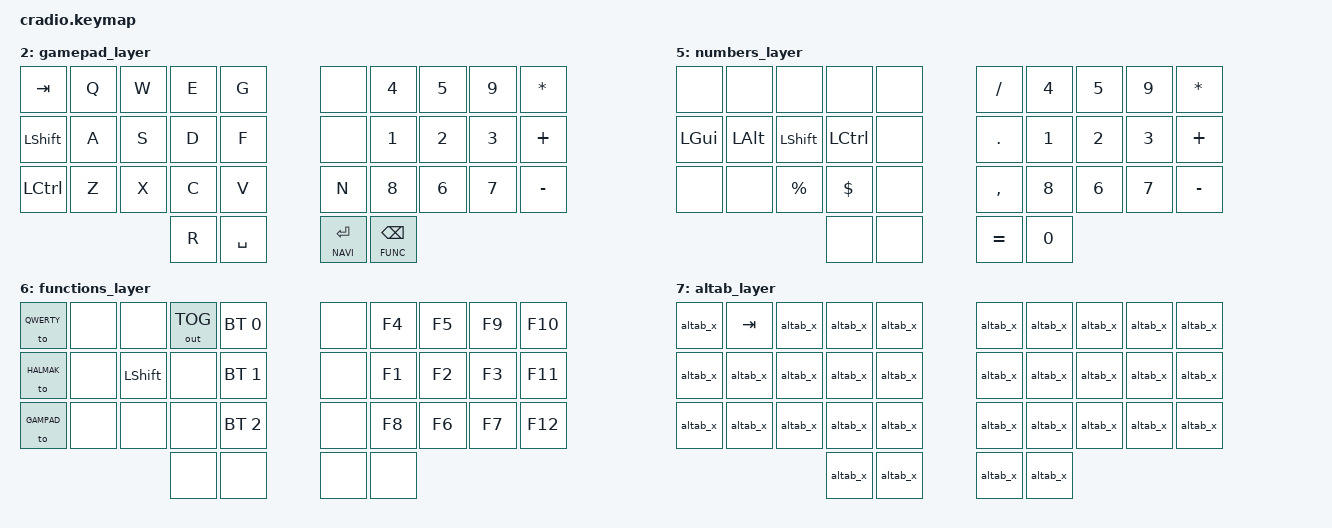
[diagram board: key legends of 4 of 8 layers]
// Copyright (c) 2022 The ZMK Contributors
// Copyright (c) 2022 Kai Evans
// SPDX-License-Identifier: MIT

#include <behaviors.dtsi>
#include <dt-bindings/zmk/outputs.h>
#include <dt-bindings/zmk/keys.h>
#include <dt-bindings/zmk/bt.h>

&lt {
	flavor = "hold-preferred";
};

&caps_word {
	continue-list = <UNDER MINUS BSPC RSHFT LSHFT>;
};

#define HALMAK 0
#define QWERTY 1
#define GAMPAD 2
#define NAVI   3
#define EDIT   4
#define NUMS   5
#define FUNC   6
#define ALTAB  7

#define QWERTY_MOD_MACRO(name, mod)            \
name: name##_macro {                           \
	label = #name;                             \
	compatible = "zmk,behavior-macro";         \
	#binding-cells = <0>;                      \
	wait-ms = <0>;                             \
    bindings                                   \
        = <&macro_press &mo QWERTY &kp mod>    \
        , <&macro_pause_for_release>           \
        , <&macro_release &mo QWERTY &kp mod>; \
};

/ {
    macros {
        QWERTY_MOD_MACRO(qalt, LALT)
        QWERTY_MOD_MACRO(qgui, LGUI)
        QWERTY_MOD_MACRO(qctl, LCTRL)

        // the edit layer altab
        edit_altab_halmak: edit_altab_layer_tap_halmak {
            label = "edit_altab_layer_tap_halmak";
            compatible = "zmk,behavior-macro";
	        #binding-cells = <0>;
	        wait-ms = <0>;
            tap-ms = <0>;
            bindings
                = <&macro_press &to EDIT>
                , <&macro_pause_for_release>
                , <&macro_release &kp LCTRL>
                , <&macro_tap &to HALMAK>;
        };

        edit_altab_qwerty: edit_altab_layer_tap_qwerty {
            label = "edit_altab_layer_tap_qwerty";
            compatible = "zmk,behavior-macro";
	        #binding-cells = <0>;
	        wait-ms = <0>;
            tap-ms = <0>;
            bindings
                = <&macro_press &to EDIT>
                , <&macro_pause_for_release>
                , <&macro_release &kp LCTRL>
                , <&macro_tap &to QWERTY>;
        };

        altab: alt_tab_enter {
            label = "alt_tab_enter";
            compatible = "zmk,behavior-macro";
            #binding-cells = <0>;
            wait-ms = <10>;
            tap-ms = <20>;
            bindings =
                <&macro_press &kp LCTRL>,
                <&macro_tap &kp TAB &to ALTAB>;
        };
        altab_x: alt_tab_leave {
            label = "alt_tab_leave";
            compatible = "zmk,behavior-macro";
            #binding-cells = <0>;
            wait-ms = <10>;
            tap-ms = <20>;
            bindings =
                <&macro_release &kp LCTRL>,
                <&macro_tap &to 0>;
        };
    };
};

#define HOME_ROW_MOD_TAP(name, macro)      \
name: name##_mod_tap {                     \
    label = #name;                         \
    compatible = "zmk,behavior-hold-tap";  \
    #binding-cells = <2>;                  \
    flavor = "balanced";                   \
    tapping-term-ms = <200>;               \
    quick-tap-ms = <150>;                  \
    global-quick-tap;                      \
    bindings = <macro>, <&kp>;             \
};

/ {
    behaviors {
        HOME_ROW_MOD_TAP(ht_alt, &qalt)
        HOME_ROW_MOD_TAP(ht_gui, &qgui)
        HOME_ROW_MOD_TAP(ht_ctl, &qctl)
        sht: quick_hold_tap {
            label = "quick_hold_tap";
            compatible = "zmk,behavior-hold-tap";
            #binding-cells = <2>;
            flavor = "balanced";
            tapping-term-ms = <170>;
            quick-tap-ms = <130>;
            global-quick-tap;
            bindings = <&kp>, <&kp>;
        };
        eth: edit_layer_tap_halmak {
            label = "edit_layer_with_altab_halmak";
            compatible = "zmk,behavior-hold-tap";
            flavor = "tap-preferred";
            tapping-term-ms = <200>;
            #binding-cells = <2>;
            bindings = <&edit_altab_halmak>, <&kp>;
        };
        etq: edit_layer_tap_qwerty {
            label = "edit_layer_with_altab_qwerty";
            compatible = "zmk,behavior-hold-tap";
            flavor = "tap-preferred";
            tapping-term-ms = <200>;
            #binding-cells = <2>;
            bindings = <&edit_altab_qwerty>, <&kp>;
        };
    };
};

#define HRML(k1,k2,k3,k4) &ht_gui 0 k1  &ht_alt 0 k2  &sht LSHFT k3  &ht_ctl 0 k4
#define HRMR(k1,k2,k3,k4) &ht_ctl 0 k1  &sht RSHFT k2  &ht_alt 0 k3  &ht_gui 0 k4


/ {
    keymap {
        compatible = "zmk,keymap";
        halmak_layer {
            bindings = <
        //╭──────────┬──────────┬──────────┬──────────┬──────────╮   ╭──────────┬──────────┬──────────┬──────────┬──────────╮
        //│  W       │  L       │  R       │  B       │  Z       │   │  ;       │  Q       │  U       │  D       │  J       │
            &kp W      &kp L      &kp R      &kp B      &kp Z          &kp SEMI   &kp Q      &kp U      &kp D      &kp J
        //├──────────┼──────────┼──────────┼──────────┼──────────┤   ├──────────┼──────────┼──────────┼──────────┼──────────┤
        //│  S       │  H       │  N       │  T       │  ,       │   │  .       │  A       │  E       │  O       │  I       │
            HRML(S,        H,         N,         T)     &kp COMMA      &kp DOT   HRMR(A,        E,         O,        I)
        //├──────────┼──────────┼──────────┼──────────┼──────────┤   ├──────────┼──────────┼──────────┼──────────┼──────────┤
        //│  F       │  M       │  V       │  C       │  /       │   │  G       │  P       │  X       │  K       │  Y       │
            &kp F      &kp M      &kp V      &kp C      &kp FSLH          &kp G      &kp P   &kp X     &kp K       &kp Y
        //╰──────────┴──────────┴──────────┼──────────┼──────────┤   ├──────────┼──────────┼──────────┴──────────┴──────────╯
                                       &lt NUMS TAB  &eth EDIT SPACE  &lt NAVI ENTER &lt FUNC BSPC
        //                                 ╰──────────┴──────────╯   ╰──────────┴──────────╯
            >;
        };

        qwerty_layer {
            bindings = <
        //╭──────────┬──────────┬──────────┬──────────┬──────────╮   ╭──────────┬──────────┬──────────┬──────────┬──────────╮
        //│  Q       │  W       │  E       │  R       │  T       │   │  Y       │  U       │  I       │  O       │  P       │
            &kp Q      &kp W      &kp E      &kp R      &kp T          &kp Y      &kp U      &kp I      &kp O      &kp P
        //├──────────┼──────────┼──────────┼──────────┼──────────┤   ├──────────┼──────────┼──────────┼──────────┼──────────┤
        //│  A       │  S       │  D       │  F       │  G       │   │  H       │  J       │  K       │  L       │ ;        │
            HRML(A,        S,         D,         F)     &kp G          &kp H      HRMR(J,        K,         L,        SEMI)
        //├──────────┼──────────┼──────────┼──────────┼──────────┤   ├──────────┼──────────┼──────────┼──────────┼──────────┤
        //│  Z       │  X       │  C       │  V       │  B       │   │  N       │  M       │ , <      │ . >      │ / ?      │
            &kp Z      &kp X      &kp C      &kp V      &kp B          &kp N      &kp M      &kp COMMA  &kp DOT    &kp FSLH
        //╰──────────┴──────────┴──────────┼──────────┼──────────┤   ├──────────┼──────────┼──────────┴──────────┴──────────╯
                                       &lt NUMS TAB  &etq EDIT SPACE  &lt NAVI ENTER &lt FUNC BSPC
        //                                 ╰──────────┴──────────╯   ╰──────────┴──────────╯
            >;
        };

        gamepad_layer {
            bindings = <
        //╭──────────┬──────────┬──────────┬──────────┬──────────╮   ╭──────────┬──────────┬──────────┬──────────┬──────────╮
        //│          │          │          │          │          │   │          │          │          │          │          │
          &kp TAB    &kp Q      &kp W      &kp E      &kp G          &none      &kp N4     &kp N5     &kp N9     &kp STAR
        //├──────────┼──────────┼──────────┼──────────┼──────────┤   ├──────────┼──────────┼──────────┼──────────┼──────────┤
        //│          │          │          │          │          │   │          │          │          │          │          │
          &kp LSHFT  &kp A      &kp S      &kp D      &kp F          &none      &kp N1     &kp N2     &kp N3     &kp PLUS 
        //├──────────┼──────────┼──────────┼──────────┼──────────┤   ├──────────┼──────────┼──────────┼──────────┼──────────┤
        //│          │          │          │          │          │   │          │          │          │          │          │
          &kp LCTRL  &kp Z      &kp X      &kp C      &kp V          &kp N      &kp N8     &kp N6     &kp N7     &kp MINUS
        //╰──────────┴──────────┴──────────┼──────────┼──────────┤   ├──────────┼──────────┼──────────┴──────────┴──────────╯
                                           &kp R      &kp SPACE      &lt NAVI ENTER &lt FUNC BSPC
        //                                 ╰──────────┴──────────╯   ╰──────────┴──────────╯
            >;
        };

        navigation_layer {
            bindings = <
        //╭──────────┬──────────┬──────────┬──────────┬──────────╮   ╭──────────┬──────────┬──────────┬──────────┬──────────╮
        //│ ^        │  {       │  *       │  }       │          │   │          │ HOME     │ UP       │ END      │ PAGE UP  │
          &kp CARET  &kp LBRC   &kp ASTRK  &kp RBRC   &none          &none      &kp HOME   &kp UP     &kp END    &kp PG_UP
        //├──────────┼──────────┼──────────┼──────────┼──────────┤   ├──────────┼──────────┼──────────┼──────────┼──────────┤
        //│ !        │  (       │  #       │  )       │          │   │          │ LEFT     │ DOWN     │ RIGHT    │ PAGE DN  │
        HRML(EXCL,      LPAR,     HASH,       RPAR)   &none          &none      &kp LEFT   &kp DOWN   &kp RIGHT  &kp PG_DN
        //├──────────┼──────────┼──────────┼──────────┼──────────┤   ├──────────┼──────────┼──────────┼──────────┼──────────┤
        //│ ?        │  @       │  %       │  $       │          │   │          │          │          │          │          │
          &kp QMARK  &kp AT     &kp PRCNT  &kp DLLR   &none          &none      &none      &none      &none      &none
        //╰──────────┴──────────┴──────────┼──────────┼──────────┤   ├──────────┼──────────┼──────────┴──────────┴──────────╯
                                           &none      &kp UNDER      &none      &none
        //                                 ╰──────────┴──────────╯   ╰──────────┴──────────╯
            >;
        };

        editing_layer {
            bindings = <
        //╭──────────┬──────────┬──────────┬──────────┬──────────╮   ╭──────────┬──────────┬──────────┬──────────┬──────────╮
        //│ ESC      │  ALTAB   │  ALTLD   │          │          │   │          │ [        │ -        │ ]        │ `        │
          &kp ESC    &altab     &kp LC(TILDE) &none   &none          &none      &kp LBKT   &kp MINUS  &kp RBKT   &kp GRAVE
        //├──────────┼──────────┼──────────┼──────────┼──────────┤   ├──────────┼──────────┼──────────┼──────────┼──────────┤
        //│ UNDO     │  CUT     │  COPY    │  PASTE   │ REDO     │   │  ~       │ <        │ =        │ >        │ '        │
        HRML( LC(Z),   LC(X),     LC(C),     LC(V))  &kp LC(LS(Z))   &kp TILDE  &kp LT     &kp EQUAL  &kp GT  &kp SQT
        //├──────────┼──────────┼──────────┼──────────┼──────────┤   ├──────────┼──────────┼──────────┼──────────┼──────────┤
        //│          │          │          │          │          │   │          │ /        │ |        │ \        │ "        │
          &none      &none      &none      &none      &none          &none      &kp FSLH   &kp PIPE   &kp BSLH   &kp DQT
        //╰──────────┴──────────┴──────────┼──────────┼──────────┤   ├──────────┼──────────┼──────────┴──────────┴──────────╯
                                           &none      &none          &kp AMPS   &kp DEL
        //                                 ╰──────────┴──────────╯   ╰──────────┴──────────╯
            >;
        };

        numbers_layer {
            bindings = <
        //╭──────────┬──────────┬──────────┬──────────┬──────────╮   ╭──────────┬──────────┬──────────┬──────────┬──────────╮
        //│          │          │          │          │          │   │  /       │ 4        │ 5        │ 9        │ *        │
          &none      &none      &none      &none      &none          &kp FSLH &kp N4    &kp N5     &kp N9     &kp STAR
        //├──────────┼──────────┼──────────┼──────────┼──────────┤   ├──────────┼──────────┼──────────┼──────────┼──────────┤
        //│          │          │          │          │          │   │ .        │ 1        │ 2        │ 3        │ +        │
          &kp LGUI   &kp LALT   &kp LSHFT  &kp LCTRL  &none          &kp DOT &kp N1     &kp N2     &kp N3     &kp PLUS
        //├──────────┼──────────┼──────────┼──────────┼──────────┤   ├──────────┼──────────┼──────────┼──────────┼──────────┤
        //│          │          │          │          │          │   │ ,        │ 8        │ 6        │ 7        │ -        │
          &none      &none      &kp PRCNT  &kp DLLR   &none          &kp COMMA &kp N8   &kp N6     &kp N7     &kp MINUS
        //╰──────────┴──────────┴──────────┼──────────┼──────────┤   ├──────────┼──────────┼──────────┴──────────┴──────────╯
                                           &none      &none          &kp EQUAL  &kp N0
        //                                 ╰──────────┴──────────╯   ╰──────────┴──────────╯
            >;
        };

        functions_layer {
            bindings = <
        //╭──────────┬──────────┬──────────┬──────────┬──────────╮   ╭──────────┬──────────┬──────────┬──────────┬──────────╮
        //│          │          │          │          │          │   │          │          │          │          │          │
          &to QWERTY &none      &none    &out OUT_TOG &bt BT_SEL 0   &none      &kp F4     &kp F5     &kp F9     &kp F10
        //├──────────┼──────────┼──────────┼──────────┼──────────┤   ├──────────┼──────────┼──────────┼──────────┼──────────┤
        //│          │          │          │          │          │   │          │          │          │          │          │
          &to HALMAK &none      &kp LSHFT  &none      &bt BT_SEL 1   &none      &kp F1     &kp F2     &kp F3     &kp F11
        //├──────────┼──────────┼──────────┼──────────┼──────────┤   ├──────────┼──────────┼──────────┼──────────┼──────────┤
        //│          │          │          │          │          │   │          │          │          │          │          │
          &to GAMPAD &none      &none      &none      &bt BT_SEL 2   &none      &kp F8     &kp F6     &kp F7     &kp F12
        //╰──────────┴──────────┴──────────┼──────────┼──────────┤   ├──────────┼──────────┼──────────┴──────────┴──────────╯
                                           &none      &none          &none      &none
        //                                 ╰──────────┴──────────╯   ╰──────────┴──────────╯
            >;
        };

        altab_layer {
            bindings = <
        //╭──────────┬──────────┬──────────┬──────────┬──────────╮   ╭──────────┬──────────┬──────────┬──────────┬──────────╮
        //│          │          │          │          │          │   │          │          │          │          │          │
          &altab_x   &kp TAB    &altab_x   &altab_x   &altab_x       &altab_x   &altab_x   &altab_x   &altab_x   &altab_x
        //├──────────┼──────────┼──────────┼──────────┼──────────┤   ├──────────┼──────────┼──────────┼──────────┼──────────┤
        //│          │          │          │          │          │   │          │          │          │          │          │
          &altab_x   &altab_x   &altab_x   &altab_x   &altab_x       &altab_x   &altab_x   &altab_x   &altab_x   &altab_x
        //├──────────┼──────────┼──────────┼──────────┼──────────┤   ├──────────┼──────────┼──────────┼──────────┼──────────┤
        //│          │          │          │          │          │   │          │          │          │          │          │
          &altab_x   &altab_x   &altab_x   &altab_x   &altab_x       &altab_x   &altab_x   &altab_x   &altab_x   &altab_x
        //╰──────────┴──────────┴──────────┼──────────┼──────────┤   ├──────────┼──────────┼──────────┴──────────┴──────────╯
                                           &altab_x   &altab_x       &altab_x   &altab_x
        //                                 ╰──────────┴──────────╯   ╰──────────┴──────────╯
            >;
        };
    };
};
